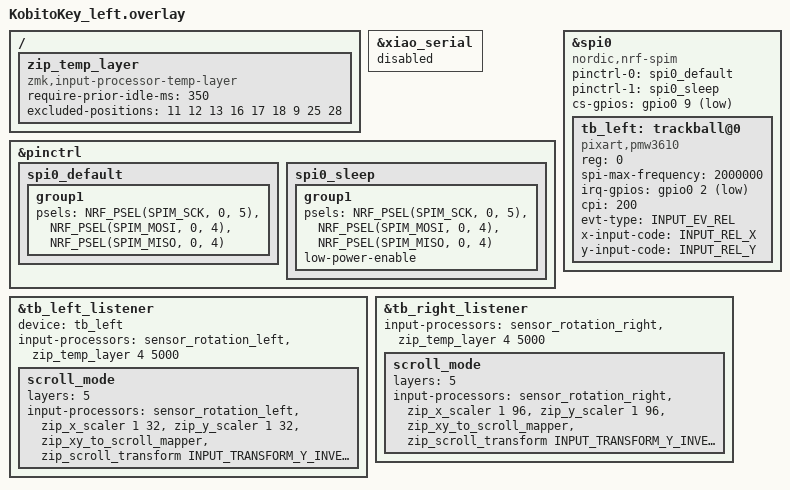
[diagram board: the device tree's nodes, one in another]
#include "kobitokey.dtsi"
#include <zephyr/dt-bindings/input/input-event-codes.h>
#include <input/processors.dtsi>
#include <input/processors/sensor_rotation.dtsi>

&xiao_serial { status = "disabled"; };

&pinctrl {
    spi0_default: spi0_default {
        group1 {
            psels = <NRF_PSEL(SPIM_SCK,  0, 5)>,
                    <NRF_PSEL(SPIM_MOSI, 0, 4)>,
                    <NRF_PSEL(SPIM_MISO, 0, 4)>;
        };
    };
    spi0_sleep: spi0_sleep {
        group1 {
            psels = <NRF_PSEL(SPIM_SCK,  0, 5)>,
                    <NRF_PSEL(SPIM_MOSI, 0, 4)>,
                    <NRF_PSEL(SPIM_MISO, 0, 4)>;
            low-power-enable;
        };
    };
};

&spi0 {
    status = "okay";
    compatible = "nordic,nrf-spim";
    pinctrl-0 = <&spi0_default>;
    pinctrl-1 = <&spi0_sleep>;
    pinctrl-names = "default", "sleep";
    cs-gpios = <&gpio0 9 GPIO_ACTIVE_LOW>;

    tb_left: trackball@0 {
        status = "okay";
        compatible = "pixart,pmw3610";
        reg = <0>;
        spi-max-frequency = <2000000>;
        irq-gpios = <&gpio0 2 (GPIO_ACTIVE_LOW | GPIO_PULL_UP)>;
        cpi = <200>;

        evt-type = <INPUT_EV_REL>;
        x-input-code = <INPUT_REL_X>;
        y-input-code = <INPUT_REL_Y>;
    };
};

/ {
    /omit-if-no-ref/ zip_temp_layer: zip_temp_layer {
        compatible = "zmk,input-processor-temp-layer";
        #input-processor-cells = <2>;
        require-prior-idle-ms = <350>;
        /* MOUSE層のクリック・戻る/進む・次ディスプレイは除外（押下しても滞留時間延長しない） */
        excluded-positions = <
            11 12 13  // S/D/F 左クリック
            16 17 18  // J/K/L 右クリック
            9         // P 次ディスプレイ
            25        // N 戻る
            28        // . 進む
        >;
    };
};

&tb_left_listener {
    status = "okay";
    device = <&tb_left>;

    /* カーソル + ボール動作時にMOUSE層(4)を自動的に5秒滞留（roba と同じ） */
    input-processors = <&sensor_rotation_left>, <&zip_temp_layer 4 5000>;

    /* SCROLL層(5)中: ボールをスクロールに変換。分母32は roba の SCROLL_TICK=32 に合わせる */
    scroll_mode {
        layers = <5>;
        input-processors =
                <&sensor_rotation_left>,
                <&zip_x_scaler 1 32>,
                <&zip_y_scaler 1 32>,
                <&zip_xy_to_scroll_mapper>,
                <&zip_scroll_transform INPUT_TRANSFORM_Y_INVERT>;
    };
};

&tb_right_listener {
    status = "okay";

    /* カーソル + ボール動作時にMOUSE層(4)を自動的に5秒滞留（roba と同じ） */
    input-processors = <&sensor_rotation_right>, <&zip_temp_layer 4 5000>;

    /* SCROLL層(5)中: 右ボール CPI 600 を左 200 @ 1/32 に合わせ、1/96 でスケール */
    scroll_mode {
        layers = <5>;
        input-processors =
                <&sensor_rotation_right>,
                <&zip_x_scaler 1 96>,
                <&zip_y_scaler 1 96>,
                <&zip_xy_to_scroll_mapper>,
                <&zip_scroll_transform INPUT_TRANSFORM_Y_INVERT>;
    };
};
